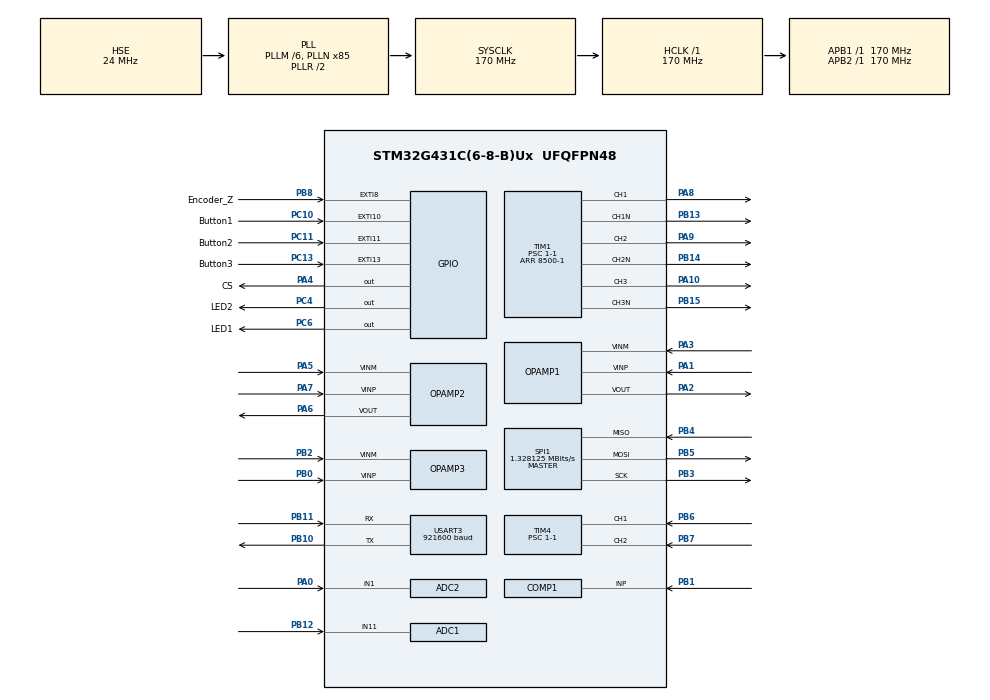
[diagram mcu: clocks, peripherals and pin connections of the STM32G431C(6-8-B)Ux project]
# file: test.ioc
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ADC1.Channel-0\#ChannelRegularConversion=ADC_CHANNEL_11
ADC1.ClockPrescaler=ADC_CLOCK_ASYNC_DIV4
ADC1.EnableInjectedConversion=ENABLE
ADC1.ExternalTrigInjecConv=ADC_EXTERNALTRIGINJEC_T1_CC4
ADC1.InjNumberOfConversion=2
ADC1.InjectedChannel-1\#ChannelInjectedConversion=ADC_CHANNEL_3
ADC1.InjectedChannel-2\#ChannelInjectedConversion=ADC_CHANNEL_12
ADC1.InjectedOffsetNumber-1\#ChannelInjectedConversion=ADC_OFFSET_NONE
ADC1.InjectedOffsetNumber-2\#ChannelInjectedConversion=ADC_OFFSET_NONE
ADC1.InjectedRank-1\#ChannelInjectedConversion=1
ADC1.InjectedRank-2\#ChannelInjectedConversion=2
ADC1.InjectedSamplingTime-1\#ChannelInjectedConversion=ADC_SAMPLETIME_6CYCLES_5
ADC1.InjectedSamplingTime-2\#ChannelInjectedConversion=ADC_SAMPLETIME_6CYCLES_5
ADC1.NbrOfConversionFlag=1
ADC1.OffsetNumber-0\#ChannelRegularConversion=ADC_OFFSET_NONE
ADC1.Rank-0\#ChannelRegularConversion=1
ADC1.Rank1_Channel=ADC_CHANNEL_3
ADC1.Rank2_Channel=ADC_CHANNEL_12
ADC1.SamplingTime-0\#ChannelRegularConversion=ADC_SAMPLETIME_2CYCLES_5
ADC1.master=1
ADC2.Channel-2\#ChannelRegularConversion=ADC_CHANNEL_1
ADC2.ClockPrescaler=ADC_CLOCK_ASYNC_DIV4
ADC2.EnableInjectedConversion=ENABLE
ADC2.EnableRegularConversion=ENABLE
ADC2.ExternalTrigInjecConv=ADC_EXTERNALTRIGINJEC_T1_CC4
ADC2.InjNumberOfConversion=1
ADC2.InjectedChannel-1\#ChannelInjectedConversion=ADC_CHANNEL_3
ADC2.InjectedOffsetNumber-1\#ChannelInjectedConversion=ADC_OFFSET_NONE
ADC2.InjectedRank-1\#ChannelInjectedConversion=1
ADC2.InjectedSamplingTime-1\#ChannelInjectedConversion=ADC_SAMPLETIME_6CYCLES_5
ADC2.NbrOfConversion=1
ADC2.NbrOfConversionFlag=1
ADC2.OffsetNumber-2\#ChannelRegularConversion=ADC_OFFSET_NONE
ADC2.Rank-2\#ChannelRegularConversion=1
ADC2.Rank1_Channel=ADC_CHANNEL_3
ADC2.SamplingTime-2\#ChannelRegularConversion=ADC_SAMPLETIME_2CYCLES_5
COMP1.BlankingSrce=COMP_BLANKINGSRC_TIM1_OC5_COMP1
Dma.Request0=USART3_TX
Dma.Request1=USART3_RX
Dma.USART3_RX.1.Direction=DMA_PERIPH_TO_MEMORY
Dma.USART3_RX.1.EventEnable=DISABLE
Dma.USART3_RX.1.Instance=DMA1_Channel2
Dma.USART3_RX.1.MemDataAlignment=DMA_MDATAALIGN_BYTE
Dma.USART3_RX.1.MemInc=DMA_MINC_ENABLE
Dma.USART3_RX.1.Mode=DMA_NORMAL
Dma.USART3_RX.1.PeriphDataAlignment=DMA_PDATAALIGN_BYTE
Dma.USART3_RX.1.PeriphInc=DMA_PINC_DISABLE
Dma.USART3_RX.1.Polarity=HAL_DMAMUX_REQ_GEN_RISING
Dma.USART3_RX.1.Priority=DMA_PRIORITY_LOW
Dma.USART3_RX.1.RequestNumber=1
Dma.USART3_RX.1.SignalID=NONE
Dma.USART3_RX.1.SyncEnable=DISABLE
Dma.USART3_RX.1.SyncPolarity=HAL_DMAMUX_SYNC_NO_EVENT
Dma.USART3_RX.1.SyncRequestNumber=1
Dma.USART3_RX.1.SyncSignalID=NONE
Dma.USART3_TX.0.Direction=DMA_MEMORY_TO_PERIPH
Dma.USART3_TX.0.EventEnable=DISABLE
Dma.USART3_TX.0.Instance=DMA1_Channel1
Dma.USART3_TX.0.MemDataAlignment=DMA_MDATAALIGN_BYTE
Dma.USART3_TX.0.MemInc=DMA_MINC_ENABLE
Dma.USART3_TX.0.Mode=DMA_NORMAL
Dma.USART3_TX.0.PeriphDataAlignment=DMA_PDATAALIGN_BYTE
Dma.USART3_TX.0.PeriphInc=DMA_PINC_DISABLE
Dma.USART3_TX.0.Polarity=HAL_DMAMUX_REQ_GEN_RISING
Dma.USART3_TX.0.Priority=DMA_PRIORITY_LOW
Dma.USART3_TX.0.RequestNumber=1
Dma.USART3_TX.0.SignalID=NONE
Dma.USART3_TX.0.SyncEnable=DISABLE
Dma.USART3_TX.0.SyncPolarity=HAL_DMAMUX_SYNC_NO_EVENT
Dma.USART3_TX.0.SyncRequestNumber=1
Dma.USART3_TX.0.SyncSignalID=NONE
Mcu.Family=STM32G4
Mcu.Name=STM32G431C(6-8-B)Ux
Mcu.Package=UFQFPN48
NVIC.ADC1_2_IRQn=true\:0\:0\:false\:false\:true\:true\:true\:true
NVIC.DMA1_Channel1_IRQn=true\:0\:0\:false\:false\:true\:false\:true\:true
NVIC.DMA1_Channel2_IRQn=true\:0\:0\:false\:false\:true\:false\:true\:true
NVIC.EXTI15_10_IRQn=true\:3\:0\:true\:false\:true\:true\:true\:true
NVIC.PriorityGroup=NVIC_PRIORITYGROUP_4
NVIC.USART3_IRQn=true\:2\:0\:true\:false\:true\:true\:true\:true
PA0.Mode=IN1-Single-Ended
PA0.Signal=ADC2_IN1
PA1.Mode=Standalone
PA1.Signal=OPAMP1_VINP
PA10.Signal=S_TIM1_CH3
PA13.Mode=Serial_Wire
PA13.Signal=SYS_JTMS-SWDIO
PA14.Mode=Serial_Wire
PA14.Signal=SYS_JTCK-SWCLK
PA2.Signal=SharedAnalog_PA2
PA3.Mode=Standalone
PA3.Signal=OPAMP1_VINM
PA4.GPIO_Label=CS
PA4.Signal=GPIO_Output
PA5.Mode=Standalone
PA5.Signal=OPAMP2_VINM
PA6.Signal=SharedAnalog_PA6
PA7.Mode=Standalone
PA7.Signal=OPAMP2_VINP
PA8.Signal=S_TIM1_CH1
PA9.Signal=S_TIM1_CH2
PB0.Mode=Standalone
PB0.Signal=OPAMP3_VINP
PB1.Signal=SharedAnalog_PB1
PB10.Mode=Asynchronous
PB10.Signal=USART3_TX
PB11.Mode=Asynchronous
PB11.Signal=USART3_RX
PB12.Mode=IN11-Single-Ended
PB12.Signal=ADC1_IN11
PB13.Mode=PWM Generation1 CH1 CH1N
PB13.Signal=TIM1_CH1N
PB14.Mode=PWM Generation2 CH2 CH2N
PB14.Signal=TIM1_CH2N
PB15.Mode=PWM Generation3 CH3 CH3N
PB15.Signal=TIM1_CH3N
PB2.Mode=Standalone
PB2.Signal=OPAMP3_VINM
PB3.Mode=Full_Duplex_Master
PB3.Signal=SPI1_SCK
PB4.Mode=Full_Duplex_Master
PB4.Signal=SPI1_MISO
PB5.Mode=Full_Duplex_Master
PB5.Signal=SPI1_MOSI
PB6.Signal=S_TIM4_CH1
PB7.Signal=S_TIM4_CH2
PB8-BOOT0.GPIO_Label=Encoder_Z
PB8-BOOT0.Signal=GPXTI8
PC10.GPIO_Label=Button1
PC10.Signal=GPXTI10
PC11.GPIO_Label=Button2
PC11.Signal=GPXTI11
PC13.GPIO_Label=Button3
PC13.Signal=GPXTI13
PC4.GPIO_Label=LED2
PC4.Signal=GPIO_Output
PC6.GPIO_Label=LED1
PC6.Signal=GPIO_Output
PF0-OSC_IN.Mode=HSE-External-Oscillator
PF0-OSC_IN.Signal=RCC_OSC_IN
PF1-OSC_OUT.Mode=HSE-External-Oscillator
PF1-OSC_OUT.Signal=RCC_OSC_OUT
ProjectManager.HeapSize=0x200
ProjectManager.StackSize=0x400
ProjectManager.TargetToolchain=MDK-ARM V5.32
RCC.ADC12Freq_Value=170000000
RCC.AHBFreq_Value=170000000
RCC.APB1Freq_Value=170000000
RCC.APB1TimFreq_Value=170000000
RCC.APB2Freq_Value=170000000
RCC.APB2TimFreq_Value=170000000
RCC.CortexFreq_Value=170000000
RCC.EXTERNAL_CLOCK_VALUE=12288000
RCC.HCLKFreq_Value=170000000
RCC.HSE_VALUE=24000000
RCC.HSI48_VALUE=48000000
RCC.HSI_VALUE=16000000
RCC.LSE_VALUE=32768
RCC.PLLM=RCC_PLLM_DIV6
RCC.PLLN=85
RCC.PLLSourceVirtual=RCC_PLLSOURCE_HSE
RCC.SYSCLKFreq_VALUE=170000000
RCC.SYSCLKSource=RCC_SYSCLKSOURCE_PLLCLK
RCC.USBFreq_Value=170000000
RCC.VCOOutputFreq_Value=340000000
SH.S_TIM1_CH1.0=TIM1_CH1,PWM Generation1 CH1 CH1N
SH.S_TIM1_CH2.0=TIM1_CH2,PWM Generation2 CH2 CH2N
SH.S_TIM1_CH3.0=TIM1_CH3,PWM Generation3 CH3 CH3N
SH.S_TIM4_CH1.0=TIM4_CH1,Encoder_Interface
SH.S_TIM4_CH2.0=TIM4_CH2,Encoder_Interface
SH.SharedAnalog_PA2.0=OPAMP1_VOUT,Standalone
SH.SharedAnalog_PA2.1=ADC1_IN3,IN3-Single-Ended
SH.SharedAnalog_PA6.0=OPAMP2_VOUT,Standalone
SH.SharedAnalog_PA6.1=ADC2_IN3,IN3-Single-Ended
SH.SharedAnalog_PB1.0=COMP1_INP,INP
SH.SharedAnalog_PB1.1=OPAMP3_VOUT,Standalone
SH.SharedAnalog_PB1.2=ADC1_IN12,IN12-Single-Ended
SPI1.BaudRatePrescaler=SPI_BAUDRATEPRESCALER_128
SPI1.CLKPhase=SPI_PHASE_2EDGE
SPI1.CLKPolarity=SPI_POLARITY_HIGH
SPI1.CalculateBaudRate=1.328125 MBits/s
SPI1.DataSize=SPI_DATASIZE_16BIT
SPI1.Direction=SPI_DIRECTION_2LINES
SPI1.Mode=SPI_MODE_MASTER
SPI1.VirtualType=VM_MASTER
STMicroelectronics.X-CUBE-ALGOBUILD.1.4.0.LibraryCcDSPOoLibraryJjDSPOoLibrary=true
TIM1.BreakFilter=15
TIM1.BreakState=TIM_BREAK_ENABLE
TIM1.Channel-PWM\ Generation1\ CH1\ CH1N=TIM_CHANNEL_1
TIM1.Channel-PWM\ Generation2\ CH2\ CH2N=TIM_CHANNEL_2
TIM1.Channel-PWM\ Generation3\ CH3\ CH3N=TIM_CHANNEL_3
TIM1.Channel-PWM\ Generation4\ No\ Output=TIM_CHANNEL_4
TIM1.Channel-PWM\ Generation5\ No\ Output=TIM_CHANNEL_5
TIM1.ClockDivision=TIM_CLOCKDIVISION_DIV2
TIM1.CounterMode=TIM_COUNTERMODE_CENTERALIGNED1
TIM1.DeadTime=60
TIM1.OCMode_PWM-PWM\ Generation4\ No\ Output=TIM_OCMODE_PWM2
TIM1.PeriodNoDither=8500-1
TIM1.Prescaler=1-1
TIM1.PulseNoDither_4=8500-2
TIM1.RepetitionCounter=2-1
TIM1.SourceBRKCOMP1=TIM_BREAKINPUTSOURCE_ENABLE
TIM1.TIM_MasterOutputTrigger=TIM_TRGO_OC4REF
TIM4.EncoderMode=TIM_ENCODERMODE_TI12
TIM4.IC1Filter=15
TIM4.IC2Filter=15
TIM4.PeriodNoDither=4096-1
TIM4.Prescaler=1-1
USART3.BaudRate=921600
USART3.VirtualMode-Asynchronous=VM_ASYNC
VP_COMP1_VS_DAC3OUT1.Mode=INM_DAC3OUT1
VP_DAC3_VS_DACI1.Mode=DAC_OUT1_Int
VP_STMicroelectronics.X-CUBE-ALGOBUILD_VS_DSPOoLibraryJjLibrary_1.4.0_1.4.0.Mode=DSPOoLibraryJjLibrary
VP_SYS_VS_DBSignals.Mode=DisableDeadBatterySignals
VP_TIM1_VS_ClockSourceINT.Mode=Internal
VP_TIM1_VS_no_output4.Mode=PWM Generation4 No Output
VP_TIM1_VS_no_output5.Mode=PWM Generation5 No Output
board=custom

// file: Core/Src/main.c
/* USER CODE BEGIN Header */
/**
  ******************************************************************************
  * @file           : main.c
  * @brief          : Main program body
  ******************************************************************************
  * @attention
  *
  * Copyright (c) 2026 STMicroelectronics.
  * All rights reserved.
  *
  * This software is licensed under terms that can be found in the LICENSE file
  * in the root directory of this software component.
  * If no LICENSE file comes with this software, it is provided AS-IS.
  *
  ******************************************************************************
  */
/* USER CODE END Header */
#include "main.h"
#include "adc.h"
#include "comp.h"
#include "dac.h"
#include "dma.h"
#include "opamp.h"
#include "spi.h"
#include "tim.h"
#include "usart.h"
#include "gpio.h"

/* USER CODE BEGIN Includes */
#include "Motor_Task_func.h"
#include "Motor_Comm_func.h"
#include "Motor_Struct.h"
/* USER CODE END Includes */

void SystemClock_Config(void);

int main(void)
{

  /* MCU Configuration--------------------------------------------------------*/

  /* Reset of all peripherals, Initializes the Flash interface and the Systick. */
  HAL_Init();

  /* Configure the system clock */
  SystemClock_Config();

  /* Initialize all configured peripherals */
  MX_GPIO_Init();
  MX_DMA_Init();
  MX_COMP1_Init();
  MX_DAC3_Init();
  MX_OPAMP1_Init();
  MX_OPAMP2_Init();
  MX_OPAMP3_Init();
  MX_TIM1_Init();
  MX_TIM4_Init();
  MX_ADC1_Init();
  MX_ADC2_Init();
  MX_USART3_UART_Init();
  MX_SPI1_Init();
  /* USER CODE BEGIN 2 */

BSP_Init();
m_app_Init();

  /* USER CODE END 2 */

  /* Infinite loop */
  while (1)
  {

  }
}

void SystemClock_Config(void)
{
  RCC_OscInitTypeDef RCC_OscInitStruct = {0};
  RCC_ClkInitTypeDef RCC_ClkInitStruct = {0};

  /** Configure the main internal regulator output voltage
  */
  HAL_PWREx_ControlVoltageScaling(PWR_REGULATOR_VOLTAGE_SCALE1_BOOST);

  /** Initializes the RCC Oscillators according to the specified parameters
  * in the RCC_OscInitTypeDef structure.
  */
  RCC_OscInitStruct.OscillatorType = RCC_OSCILLATORTYPE_HSE;
  RCC_OscInitStruct.HSEState = RCC_HSE_ON;
  RCC_OscInitStruct.PLL.PLLState = RCC_PLL_ON;
  RCC_OscInitStruct.PLL.PLLSource = RCC_PLLSOURCE_HSE;
  RCC_OscInitStruct.PLL.PLLM = RCC_PLLM_DIV6;
  RCC_OscInitStruct.PLL.PLLN = 85;
  RCC_OscInitStruct.PLL.PLLP = RCC_PLLP_DIV2;
  RCC_OscInitStruct.PLL.PLLQ = RCC_PLLQ_DIV2;
  RCC_OscInitStruct.PLL.PLLR = RCC_PLLR_DIV2;
  if (HAL_RCC_OscConfig(&RCC_OscInitStruct) != HAL_OK)
  {
    Error_Handler();
  }

  /** Initializes the CPU, AHB and APB buses clocks
  */
  RCC_ClkInitStruct.ClockType = RCC_CLOCKTYPE_HCLK|RCC_CLOCKTYPE_SYSCLK
                              |RCC_CLOCKTYPE_PCLK1|RCC_CLOCKTYPE_PCLK2;
  RCC_ClkInitStruct.SYSCLKSource = RCC_SYSCLKSOURCE_PLLCLK;
  RCC_ClkInitStruct.AHBCLKDivider = RCC_SYSCLK_DIV1;
  RCC_ClkInitStruct.APB1CLKDivider = RCC_HCLK_DIV1;
  RCC_ClkInitStruct.APB2CLKDivider = RCC_HCLK_DIV1;

  if (HAL_RCC_ClockConfig(&RCC_ClkInitStruct, FLASH_LATENCY_4) != HAL_OK)
  {
    Error_Handler();
  }
}

void Error_Handler(void)
{
  __disable_irq();
  while (1)
  {
  }
}
